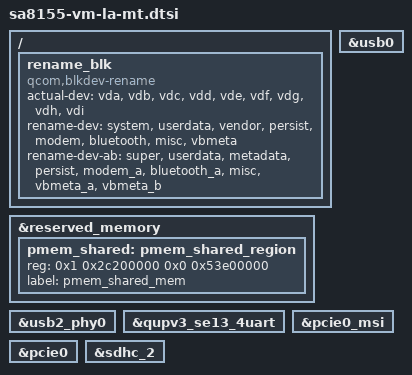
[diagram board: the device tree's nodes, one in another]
&reserved_memory {
	pmem_shared: pmem_shared_region {
		reg = <0x1 0x2c200000 0x0 0x53e00000>;
		label = "pmem_shared_mem";
	};
};

#include "display/quin-vm-display-la.dtsi"

/ {
	rename_blk: rename_blk {
		compatible = "qcom,blkdev-rename";
		actual-dev = "vda", "vdb", "vdc",
				"vdd", "vde", "vdf",
				"vdg", "vdh", "vdi";
		rename-dev = "system", "userdata", "vendor",
				"persist", "modem", "bluetooth",
				"misc", "vbmeta";
		rename-dev-ab = "super", "userdata", "metadata",
				"persist", "modem_a", "bluetooth_a",
				"misc", "vbmeta_a", "vbmeta_b";
	};

	/delete-node/ cpus;
};

&usb0 {
	status = "ok";
};

&usb2_phy0 {
	status = "ok";
};

&qupv3_se13_4uart {
	status = "ok";
};

&pcie0_msi {
	status = "ok";
};

&pcie0 {
	status = "ok";
};

&sdhc_2 {
	status = "ok";
};
